# HK32F0301MxxC register map
Vendor: HKMicroChip Ltd.; Series: HK32F0301MxxC; File version: 0.9
CPU: CM0 r0p0, little endian, no MPU, no FPU, 3 interrupt priority bits
Registers are 32-bit, read-write, reset 0x0 unless marked. A register's access mark holds for its fields unless they carry their own. Offsets are from the block's base; [hi:lo] are bit positions.

## IWDG
Base 0x40003000
0x00 KR wo
  [15:0] KEY — Key value
0x04 PR
  [2:0] PR — Prescaler divider
0x08 RLR reset 0xFFF
  [11:0] RL — Watchdog counter reload value
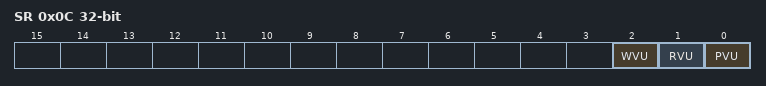
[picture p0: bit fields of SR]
0x0C SR ro
  [2] WVU — Watchdog counter window value update
  [1] RVU — Watchdog counter reload value update
  [0] PVU — Watchdog prescaler value update
0x10 WINR reset 0xFFF
  [11:0] WIN — Watchdog counter window value

## WWDG
Base 0x40002C00
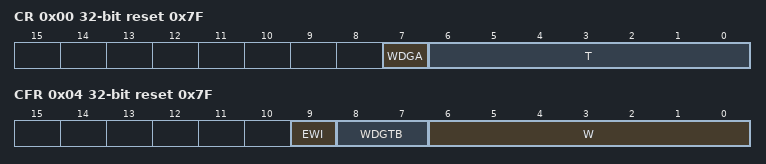
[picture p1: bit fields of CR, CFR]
0x00 CR reset 0x7F
  [7] WDGA — Activation bit
  [6:0] T — 7-bit counter (MSB to LSB)
0x04 CFR reset 0x7F
  [9] EWI — Early wakeup interrupt
  [8:7] WDGTB — Timer base
  [6:0] W — 7-bit window value
0x08 SR
  [0] EWIF — Early wakeup interrupt flag

## UART1
Base 0x40013800
Same registers: UART2 0x40013C00
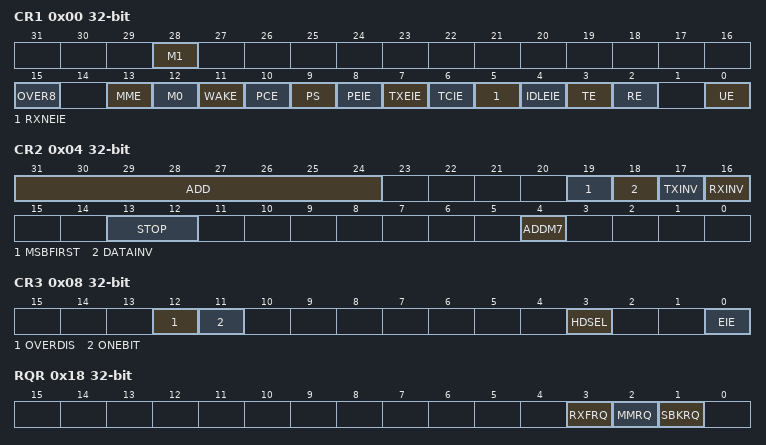
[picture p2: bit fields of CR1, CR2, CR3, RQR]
0x00 CR1
  [28] M1 — Word length
  [15] OVER8 — Oversampling mode
  [13] MME — Mute mode enable
  [12] M0 — Word length
  [11] WAKE — Receiver wakeup method
  [10] PCE — Parity control enable
  [9] PS — Parity selection
  [8] PEIE — PE interrupt enable
  [7] TXEIE — TXE interrupt enable
  [6] TCIE — Transmission complete interrupt enable
  [5] RXNEIE — RXNE interrupt enable
  [4] IDLEIE — IDLE interrupt enable
  [3] TE — Transmitter enable
  [2] RE — Receiver enable
  [0] UE — UART enable
0x04 CR2
  [31:24] ADD — Address of the UART node
  [19] MSBFIRST — Most significant bit first
  [18] DATAINV — Binary data inversion
  [17] TXINV — TX pin active level inversion
  [16] RXINV — RX pin active level inversion
  [13:12] STOP — STOP bits
  [4] ADDM7 — With 7-bit Address Detection/4-bit Address Detection
0x08 CR3
  [12] OVERDIS — Overrun Disable
  [11] ONEBIT — One sample bit method enable
  [3] HDSEL — Half-duplex selection
  [0] EIE — Error interrupt enable
0x0C BRR
  [15:0] BRR — DIV of UART
0x18 RQR wo
  [3] RXFRQ — Receive data flush request
  [2] MMRQ — Mute mode request
  [1] SBKRQ — Send break request
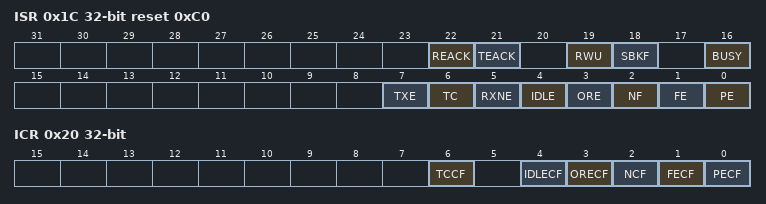
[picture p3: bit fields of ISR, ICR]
0x1C ISR ro reset 0xC0
  [22] REACK — Receive enable acknowledge flag
  [21] TEACK — Transmit enable acknowledge flag
  [19] RWU — Receiver wakeup from Mute mode
  [18] SBKF — Send break flag
  [16] BUSY — Busy flag
  [7] TXE — Transmit data register empty
  [6] TC — Transmission complete
  [5] RXNE — Receive data register not empty
  [4] IDLE — Idle line detected
  [3] ORE — Overrun error
  [2] NF — START bit Noise detection flag
  [1] FE — Framing error
  [0] PE — Parity error
0x20 ICR
  [6] TCCF — Transmission complete clear flag
  [4] IDLECF — Idle line detected clear flag
  [3] ORECF — Overrun error clear flag
  [2] NCF — Noise detected clear flag
  [1] FECF — Framing error clear flag
  [0] PECF — Parity error clear flag
0x24 RDR ro
  [8:0] RDR — Receive data value
0x28 TDR
  [8:0] TDR — Transmit data value

## I2C
Base 0x40005400
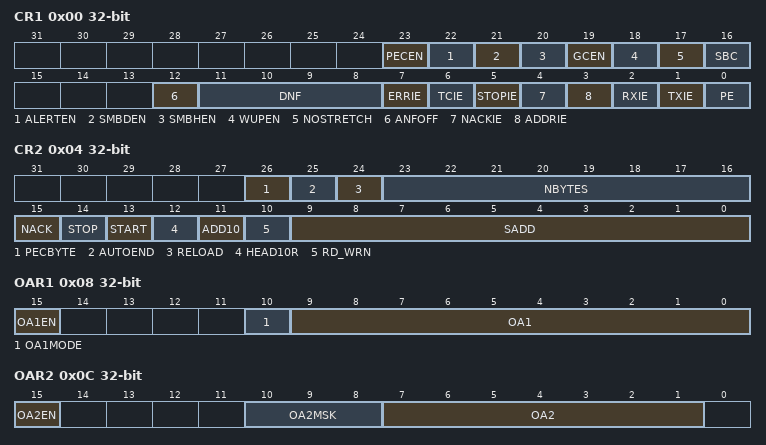
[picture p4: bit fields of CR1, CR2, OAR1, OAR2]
0x00 CR1
  [23] PECEN — PEC enable
  [22] ALERTEN — SMBus alert enable
  [21] SMBDEN — SMBus Device Default address enable
  [20] SMBHEN — SMBus Host address enable
  [19] GCEN — General call enable
  [18] WUPEN — Wakeup from Stop mode enable
  [17] NOSTRETCH — Clock stretching disable
  [16] SBC — Slave byte control
  [12] ANFOFF — Analog noise filter OFF
  [11:8] DNF — Digital noise filter
  [7] ERRIE — Error interrupts enable
  [6] TCIE — Transfer Complete interrupt enable
  [5] STOPIE — STOP detection Interrupt enable
  [4] NACKIE — Not acknowledge received Interrupt enable
  [3] ADDRIE — Address match Interrupt enable , slave only
  [2] RXIE — RX Interrupt enable
  [1] TXIE — TX Interrupt enable
  [0] PE — Peripheral enable
0x04 CR2
  [26] PECBYTE — Packet error checking byte
  [25] AUTOEND — Automatic end mode ,master mode
  [24] RELOAD — NBYTES reload mode
  [23:16] NBYTES — Number of bytes
  [15] NACK — NACK generation ,slave mode
  [14] STOP — STOP generation,master mode
  [13] START — Start generation
  [12] HEAD10R — Address header only read direction 10-bit ,master receiver mode
  [11] ADD10 — Addressing mode 10-bit，master mode
  [10] RD_WRN — Transfer direction, master mode
  [9:0] SADD — Slave address bit 9:0 in master mode
0x08 OAR1
  [15] OA1EN — Own Address 1 enable
  [10] OA1MODE — Own Address 1 10-bit mode
  [9:0] OA1 — Interface address 9:8 bit
0x0C OAR2
  [15] OA2EN — Own Address 2 enable
  [10:8] OA2MSK — Own Address 2 masks
  [7:1] OA2 — Interface address
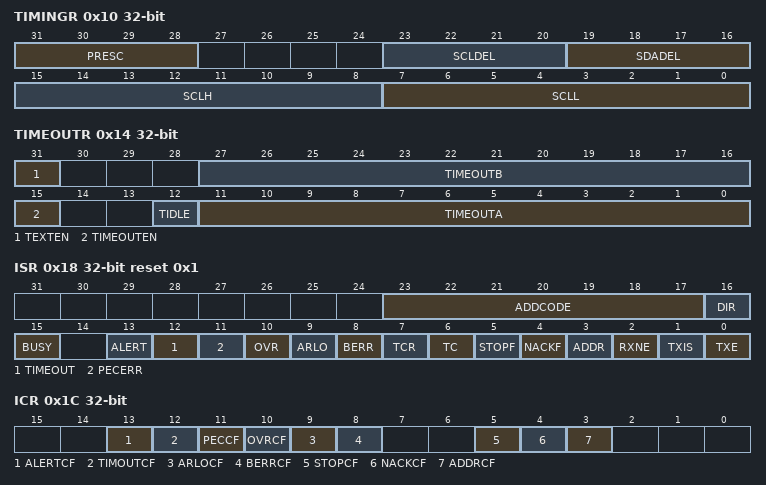
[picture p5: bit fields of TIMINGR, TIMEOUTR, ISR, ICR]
0x10 TIMINGR
  [31:28] PRESC — Timing prescaler
  [23:20] SCLDEL — Data setup time
  [19:16] SDADEL — Data hold time
  [15:8] SCLH — SCL high period ,master mode
  [7:0] SCLL — SCL low period,master mode
0x14 TIMEOUTR
  [31] TEXTEN — Extended clock timeout enable
  [27:16] TIMEOUTB — Bus timeout B
  [15] TIMEOUTEN — Clock timeout enable
  [12] TIDLE — Idle clock timeout detection
  [11:0] TIMEOUTA — Bus Timeout A
0x18 ISR access per field reset 0x1
  [23:17] ADDCODE ro — Address match code,Slave mode
  [16] DIR ro — Transfer direction ,Slave mode
  [15] BUSY ro — Bus busy
  [13] ALERT ro — SMBus alert
  [12] TIMEOUT ro — Timeout or tLOW detection flag
  [11] PECERR ro — PEC Error in reception
  [10] OVR ro — Overrun/Underrun ,slave mode
  [9] ARLO ro — Arbitration lost
  [8] BERR ro — Bus error
  [7] TCR ro — Transfer Complete Reload
  [6] TC ro — Transfer Complete ,master mode
  [5] STOPF ro — STOP detection flag
  [4] NACKF ro — Not Acknowledge received flag
  [3] ADDR ro — Address matched ,slave mode
  [2] RXNE ro — Receive data register not empty ,receivers
  [1] TXIS rw — Transmit interrupt status ,transmitters
  [0] TXE rw — Transmit data register empty,transmitters
0x1C ICR wo
  [13] ALERTCF — Alert flag clear
  [12] TIMOUTCF — Timeout detection flag clear
  [11] PECCF — PEC Error flag clear
  [10] OVRCF — Overrun/Underrun flag clear
  [9] ARLOCF — Arbitration Lost flag clear
  [8] BERRCF — Bus error flag clear
  [5] STOPCF — STOP detection flag clear
  [4] NACKCF — Not Acknowledge flag clear
  [3] ADDRCF — Address matched flag clear
0x20 PECR ro
  [7:0] PEC — Packet error checking register
0x24 RXDR ro
  [7:0] RXDATA — Receive data with 8-bit
0x28 TXDR
  [7:0] TXDATA — Transmit data with 8-bit

## SPI
Base 0x40013000
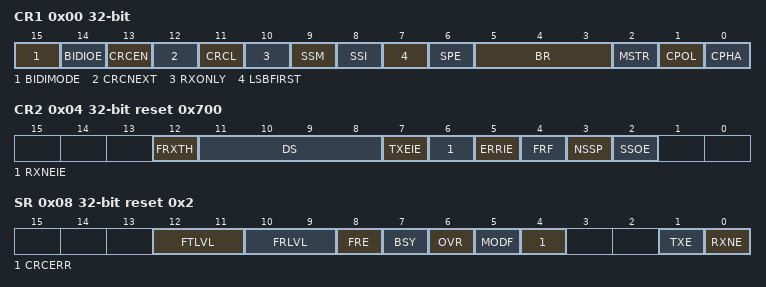
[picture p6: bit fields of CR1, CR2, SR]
0x00 CR1
  [15] BIDIMODE — Bidirectional data mode enable
  [14] BIDIOE — Output enable in bidirectional mode
  [13] CRCEN — Hardware CRC calculation enable
  [12] CRCNEXT — Transmit CRC next
  [11] CRCL — CRC length
  [10] RXONLY — Receive only mode enabled
  [9] SSM — Software slave management
  [8] SSI — Internal slave select
  [7] LSBFIRST — Frame format
  [6] SPE — SPI enable
  [5:3] BR — Baud rate control
  [2] MSTR — Master selection
  [1] CPOL — Clock polarity
  [0] CPHA — Clock phase
0x04 CR2 reset 0x700
  [12] FRXTH — FIFO reception threshold
  [11:8] DS — Data size
  [7] TXEIE — TX buffer empty interrupt enable
  [6] RXNEIE — RX buffer not empty interrupt enable
  [5] ERRIE — Error interrupt enable
  [4] FRF — Frame format
  [3] NSSP — NSS pulse management
  [2] SSOE — SS output enable
0x08 SR access per field reset 0x2
  [12:11] FTLVL ro — FIFO Transmission Level
  [10:9] FRLVL ro — FIFO reception level
  [8] FRE ro — Frame format error
  [7] BSY ro — Busy flag
  [6] OVR ro — Overrun flag
  [5] MODF ro — Mode fault
  [4] CRCERR rw — CRC error flag
  [1] TXE ro — Transmit buffer empty
  [0] RXNE ro — Receive buffer not empty
0x0C DR
  [15:0] DATA — Data message
0x10 CRCPR reset 0x7
  [15:0] CRCPOLY — CRC polynomial register
0x14 RXCRCR ro
  [15:0] RXCRC
0x18 TXCRCR ro
  [15:0] TXCRC

## DBGMCU
Base 0x40015800
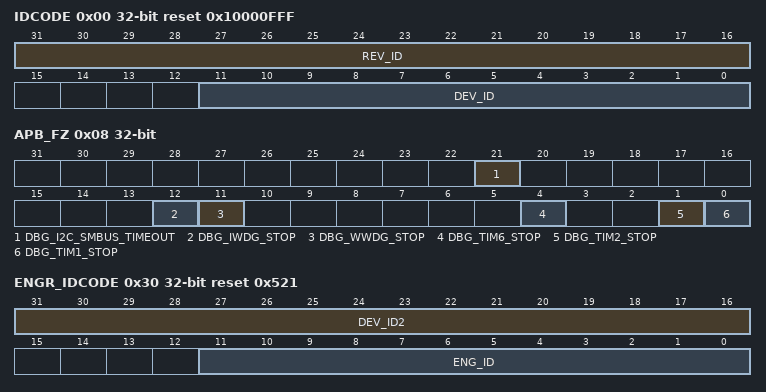
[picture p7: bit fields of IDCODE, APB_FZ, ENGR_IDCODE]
0x00 IDCODE ro reset 0x10000FFF
  [31:16] REV_ID — Revision identifier
  [11:0] DEV_ID — Device identifier
0x04 CR
  [1] DBG_STOP — Debug Stop mode
0x08 APB_FZ
  [21] DBG_I2C_SMBUS_TIMEOUT — SMBUS tiomout mode stopped when core is halted
  [12] DBG_IWDG_STOP — Debug independent watchdog stopped when core is halted
  [11] DBG_WWDG_STOP — Debug window watchdog stopped when core is halted
  [4] DBG_TIM6_STOP — TIM6 counter stopped when core is halted
  [1] DBG_TIM2_STOP — TIM2 counter stopped when core is halted
  [0] DBG_TIM1_STOP — TIM1 counter stopped when core is halted
0x30 ENGR_IDCODE ro reset 0x521
  [31:16] DEV_ID2 — Device identifier 2
  [11:0] ENG_ID — Chip identifier
